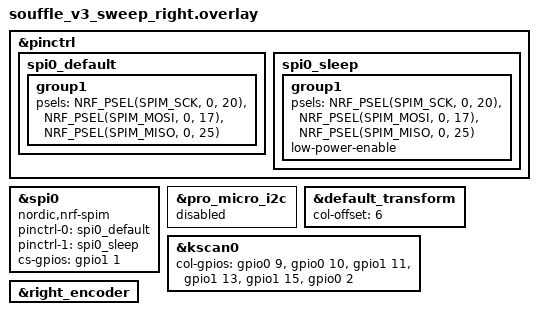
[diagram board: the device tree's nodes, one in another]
/*
 * Copyright (c) 2025 The ZMK Contributors
 * SPDX-License-Identifier: MIT
 */

#include "souffle_v3_sweep.dtsi"
#include <dt-bindings/led/led.h>

&pinctrl {
    spi0_default: spi0_default {
        group1 {
            psels = <NRF_PSEL(SPIM_SCK, 0, 20)>,
                    <NRF_PSEL(SPIM_MOSI, 0, 17)>,
                    <NRF_PSEL(SPIM_MISO, 0, 25)>;
        };
    };

    spi0_sleep: spi0_sleep {
        group1 {
            psels = <NRF_PSEL(SPIM_SCK, 0, 20)>,
                    <NRF_PSEL(SPIM_MOSI, 0, 17)>,
                    <NRF_PSEL(SPIM_MISO, 0, 25)>;
            low-power-enable;
        };
    };
};

nice_view_spi: &spi0 {
    compatible = "nordic,nrf-spim";
    status = "okay";

    pinctrl-0 = <&spi0_default>;
    pinctrl-1 = <&spi0_sleep>;
    pinctrl-names = "default", "sleep";

    cs-gpios = <&gpio1 1 GPIO_ACTIVE_HIGH>; // P1.01 for CS
};

&pro_micro_i2c {
    status = "disabled";
};

/* Display chosen node defined by nice_epaper overlay */

&default_transform {
    col-offset = <6>;
};

&kscan0 {
    col-gpios
        = <&gpio0 9  GPIO_ACTIVE_HIGH> // P0.09 - col5 (reversed for right side)
        , <&gpio0 10 GPIO_ACTIVE_HIGH> // P0.10 - col4
        , <&gpio1 11 GPIO_ACTIVE_HIGH> // P1.11 - col3
        , <&gpio1 13 GPIO_ACTIVE_HIGH> // P1.13 - col2
        , <&gpio1 15 GPIO_ACTIVE_HIGH> // P1.15 - col1
        , <&gpio0 2  GPIO_ACTIVE_HIGH> // P0.02 - col0
        ;
};

&right_encoder {
    status = "okay";
};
